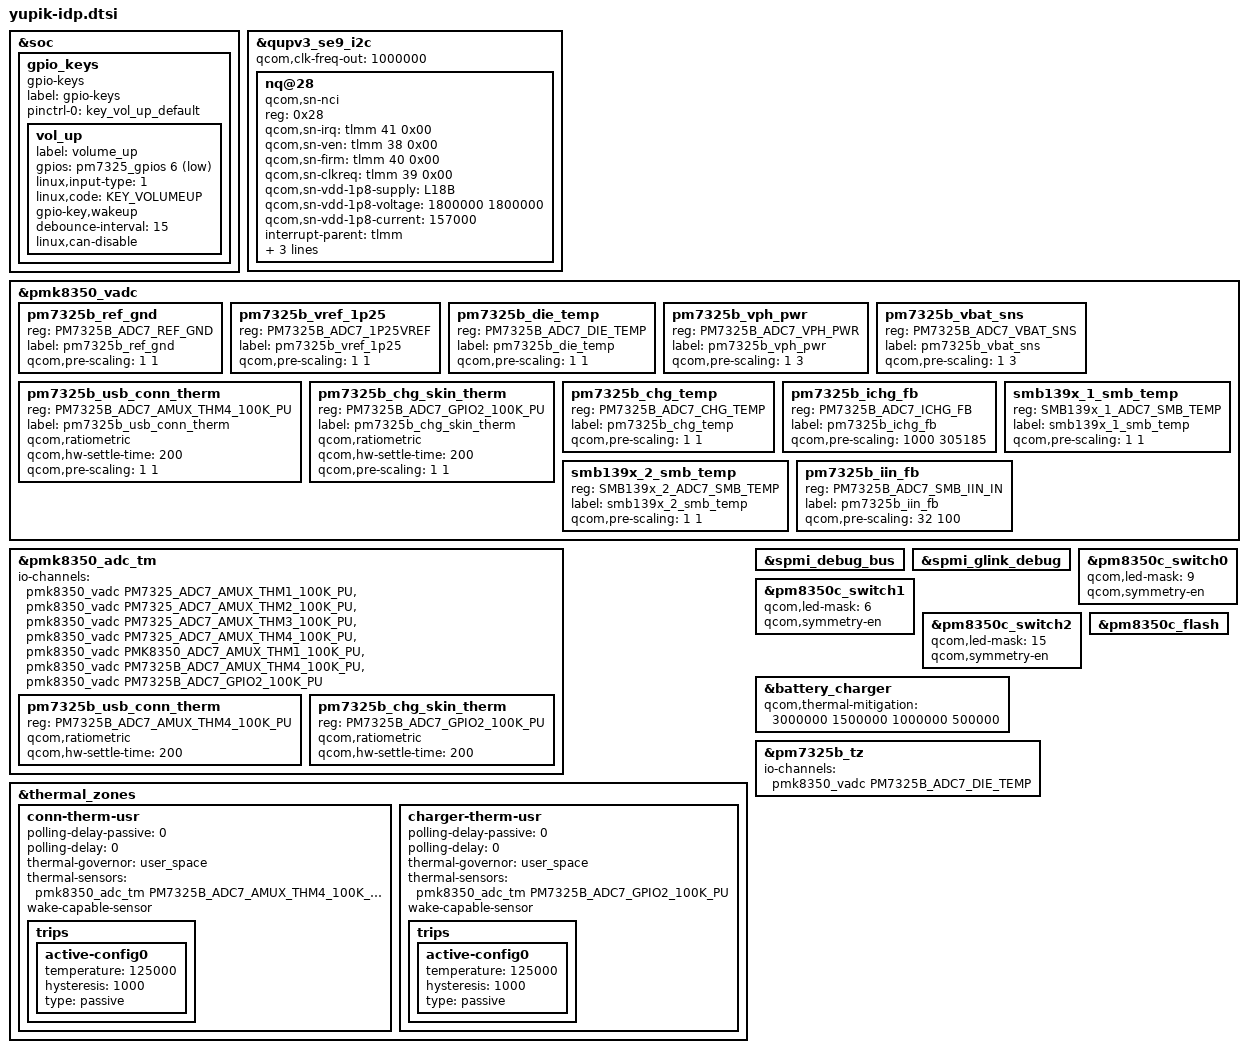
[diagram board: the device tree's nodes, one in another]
#include <dt-bindings/gpio/gpio.h>
#include <dt-bindings/iio/qcom,spmi-adc7-pm7325b.h>
#include <dt-bindings/iio/qcom,spmi-adc7-smb139x.h>
#include "yupik-pmic-overlay.dtsi"
#include "pm7325b.dtsi"

&soc {
	gpio_keys {
		compatible = "gpio-keys";
		label = "gpio-keys";

		pinctrl-names = "default";
		pinctrl-0 = <&key_vol_up_default>;

		vol_up {
			label = "volume_up";
			gpios = <&pm7325_gpios 6 GPIO_ACTIVE_LOW>;
			linux,input-type = <1>;
			linux,code = <KEY_VOLUMEUP>;
			gpio-key,wakeup;
			debounce-interval = <15>;
			linux,can-disable;
		};
	};
};

&qupv3_se9_i2c {
	status = "ok";
	qcom,clk-freq-out = <1000000>;
	#address-cells = <1>;
	#size-cells = <0>;
	nq@28 {
		compatible = "qcom,sn-nci";
		reg = <0x28>;
		qcom,sn-irq = <&tlmm 41 0x00>;
		qcom,sn-ven = <&tlmm 38 0x00>;
		qcom,sn-firm = <&tlmm 40 0x00>;
		qcom,sn-clkreq = <&tlmm 39 0x00>;
		qcom,sn-vdd-1p8-supply = <&L18B>;
		qcom,sn-vdd-1p8-voltage = <1800000 1800000>;
		qcom,sn-vdd-1p8-current = <157000>;
		interrupt-parent = <&tlmm>;
		interrupts = <41 0>;
		interrupt-names = "nfc_irq";
		pinctrl-names = "nfc_active", "nfc_suspend";
		pinctrl-0 = <&nfc_int_active &nfc_enable_active>;
		pinctrl-1 = <&nfc_int_suspend &nfc_enable_suspend>;
	};
};

&pmk8350_vadc {
	pm7325b_ref_gnd {
		reg = <PM7325B_ADC7_REF_GND>;
		label = "pm7325b_ref_gnd";
		qcom,pre-scaling = <1 1>;
	};

	pm7325b_vref_1p25 {
		reg = <PM7325B_ADC7_1P25VREF>;
		label = "pm7325b_vref_1p25";
		qcom,pre-scaling = <1 1>;
	};

	pm7325b_die_temp {
		reg = <PM7325B_ADC7_DIE_TEMP>;
		label = "pm7325b_die_temp";
		qcom,pre-scaling = <1 1>;
	};

	pm7325b_vph_pwr {
		reg = <PM7325B_ADC7_VPH_PWR>;
		label = "pm7325b_vph_pwr";
		qcom,pre-scaling = <1 3>;
	};

	pm7325b_vbat_sns {
		reg = <PM7325B_ADC7_VBAT_SNS>;
		label = "pm7325b_vbat_sns";
		qcom,pre-scaling = <1 3>;
	};

	pm7325b_usb_conn_therm {
		reg = <PM7325B_ADC7_AMUX_THM4_100K_PU>;
		label = "pm7325b_usb_conn_therm";
		qcom,ratiometric;
		qcom,hw-settle-time = <200>;
		qcom,pre-scaling = <1 1>;
	};

	pm7325b_chg_skin_therm {
		reg = <PM7325B_ADC7_GPIO2_100K_PU>;
		label = "pm7325b_chg_skin_therm";
		qcom,ratiometric;
		qcom,hw-settle-time = <200>;
		qcom,pre-scaling = <1 1>;
	};

	pm7325b_chg_temp {
		reg = <PM7325B_ADC7_CHG_TEMP>;
		label = "pm7325b_chg_temp";
		qcom,pre-scaling = <1 1>;
	};

	pm7325b_ichg_fb {
		reg = <PM7325B_ADC7_ICHG_FB>;
		label = "pm7325b_ichg_fb";
		qcom,pre-scaling = <1000 305185>;
	};

	smb139x_1_smb_temp {
		reg = <SMB139x_1_ADC7_SMB_TEMP>;
		label = "smb139x_1_smb_temp";
		qcom,pre-scaling = <1 1>;
	};

	smb139x_2_smb_temp {
		reg = <SMB139x_2_ADC7_SMB_TEMP>;
		label = "smb139x_2_smb_temp";
		qcom,pre-scaling = <1 1>;
	};

	pm7325b_iin_fb {
		reg = <PM7325B_ADC7_SMB_IIN_IN>;
		label = "pm7325b_iin_fb";
		qcom,pre-scaling = <32 100>;
	};
};

&pmk8350_adc_tm {
	io-channels = <&pmk8350_vadc PM7325_ADC7_AMUX_THM1_100K_PU>,
			<&pmk8350_vadc PM7325_ADC7_AMUX_THM2_100K_PU>,
			<&pmk8350_vadc PM7325_ADC7_AMUX_THM3_100K_PU>,
			<&pmk8350_vadc PM7325_ADC7_AMUX_THM4_100K_PU>,
			<&pmk8350_vadc PMK8350_ADC7_AMUX_THM1_100K_PU>,
			<&pmk8350_vadc PM7325B_ADC7_AMUX_THM4_100K_PU>,
			<&pmk8350_vadc PM7325B_ADC7_GPIO2_100K_PU>;

	pm7325b_usb_conn_therm {
		reg = <PM7325B_ADC7_AMUX_THM4_100K_PU>;
		qcom,ratiometric;
		qcom,hw-settle-time = <200>;
	};

	pm7325b_chg_skin_therm {
		reg = <PM7325B_ADC7_GPIO2_100K_PU>;
		qcom,ratiometric;
		qcom,hw-settle-time = <200>;
	};
};

&thermal_zones {
	conn-therm-usr {
		polling-delay-passive = <0>;
		polling-delay = <0>;
		thermal-governor = "user_space";
		thermal-sensors = <&pmk8350_adc_tm PM7325B_ADC7_AMUX_THM4_100K_PU>;
		wake-capable-sensor;
		trips {
			active-config0 {
				temperature = <125000>;
				hysteresis = <1000>;
				type = "passive";
			};
		};
	};

	charger-therm-usr {
		polling-delay-passive = <0>;
		polling-delay = <0>;
		thermal-governor = "user_space";
		thermal-sensors = <&pmk8350_adc_tm PM7325B_ADC7_GPIO2_100K_PU>;
		wake-capable-sensor;
		trips {
			active-config0 {
				temperature = <125000>;
				hysteresis = <1000>;
				type = "passive";
			};
		};
	};
};

&spmi_debug_bus {
	status = "ok";
};

&spmi_glink_debug {
	status = "ok";
};

&pm8350c_switch0 {
	qcom,led-mask = <9>; /* Channels 1 & 4 */
	qcom,symmetry-en;
};

&pm8350c_switch1 {
	qcom,led-mask = <6>; /* Channels 2 & 3 */
	qcom,symmetry-en;
};

&pm8350c_switch2 {
	qcom,led-mask = <15>; /* All Channels */
	qcom,symmetry-en;
};

&pm8350c_flash {
	status = "ok";
};

&battery_charger {
	qcom,thermal-mitigation = <3000000 1500000 1000000 500000>;
};

&pm7325b_tz {
	io-channels = <&pmk8350_vadc PM7325B_ADC7_DIE_TEMP>;
	io-channel-names = "thermal";
};
